VERSION ""

NS_ :

BS_:

BU_: ECP_Commanding_Node Modine_ECP
VAL_TABLE_ Bank_in_failsafe 1 "FAILSAFE" 0 "Not failsafe" ;
VAL_TABLE_ fan_inoperable_status 1 "Operational" 0 "INOPERABLE" ;
VAL_TABLE_ bank_status 3 "BANK_STATE_UNAVAILABLE" 2 "ALL_FANS_FAILED_IN_BANK" 1 "AT_LEAST_ONE_FAN_FAILD_IN_BANK" 0 "All Fans Operational" ;
VAL_TABLE_ FMI 0 "0 - Above normal (most severe)" 1 "1 - Below normal (most severe)" 2 "2 - Data erratic" 3 "3 - Voltage above normal" 4 "4 - Voltage below normal" 5 "5 - Current below normal" 6 "6 - Current above normal" 7 "7 - Mech system not responding" 8 "8 - Abnormal frequency" 9 "9 - Abnormal update rate" 10 "10 - Abnormal rate of change" 11 "11 - Root cause not known" 12 "12 - Bad intelligent device" 13 "13 - Out of calibration" 14 "14 - Special intstructions" 15 "15 - Above normal (least severe)" 16 "16 - Above normal (moderately)" 17 "17 - Below normal (least severe)" 18 "18 - Below normal (moderately)" 19 "19 - Recd network data in error" 20 "20 - Data drifted high" 21 "21 - Data drifted low" 31 "31 - Condition exists" ;
VAL_TABLE_ Ports 21 "Global (All ports)" 0 "Local" ;

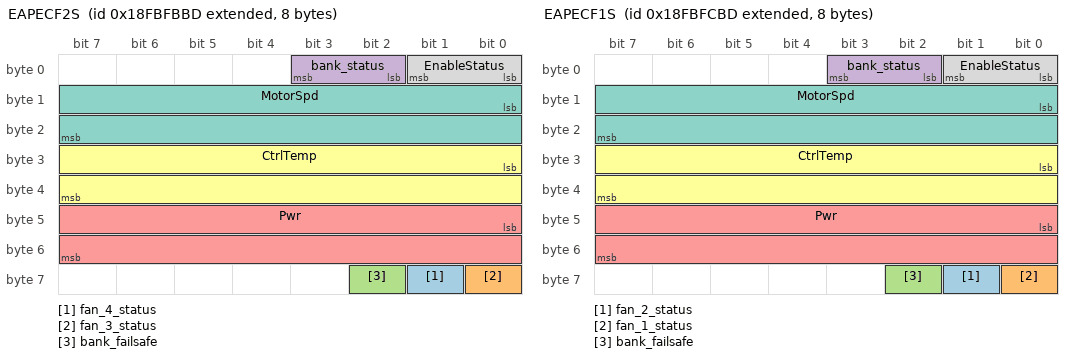
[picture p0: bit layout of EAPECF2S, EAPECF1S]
BO_ 2566650813 EAPECF2S: 8 Vector__XXX
 SG_ fan_4_status : 57|1@1+ (1,0) [0|1] "" Vector__XXX
 SG_ fan_3_status : 56|1@1+ (1,0) [0|1] "" Vector__XXX
 SG_ bank_failsafe : 58|1@1+ (1,0) [0|1] "" Vector__XXX
 SG_ bank_status : 2|2@1+ (1,0) [0|3] "" Vector__XXX
 SG_ Pwr : 40|16@1+ (0.5,0) [0|32127.5] "W" Vector__XXX
 SG_ CtrlTemp : 24|16@1+ (0.03125,-273) [-273|1734.96875] "°C" Vector__XXX
 SG_ MotorSpd : 8|16@1+ (0.5,0) [0|32127.5] "rpm" Vector__XXX
 SG_ EnableStatus : 0|2@1+ (1,0) [0|3] "" Vector__XXX

BO_ 2557984188 EAPECF2C: 8 Vector__XXX
 SG_ PercentSpdCmd : 24|8@1+ (0.5,0) [0|100] "%" Vector__XXX
 SG_ EnableCmd : 0|2@1+ (1,0) [0|3] "" Vector__XXX

BO_ 2566651069 EAPECF1S: 8 Modine_ECP
 SG_ fan_2_status : 57|1@1+ (1,0) [0|1] "" Vector__XXX
 SG_ fan_1_status : 56|1@1+ (1,0) [0|1] "" Vector__XXX
 SG_ bank_failsafe : 58|1@1+ (1,0) [0|1] "" Vector__XXX
 SG_ bank_status : 2|2@1+ (1,0) [0|3] "" Vector__XXX
 SG_ Pwr : 40|16@1+ (0.5,0) [0|32127.5] "W"  ECP_Commanding_Node
 SG_ CtrlTemp : 24|16@1+ (0.03125,-273) [-273|1734.96875] "°C"  ECP_Commanding_Node
 SG_ MotorSpd : 8|16@1+ (0.5,0) [0|32127.5] "rpm"  ECP_Commanding_Node
 SG_ EnableStatus : 0|2@1+ (1,0) [0|3] ""  ECP_Commanding_Node

BO_ 2558049724 EAPECF1C: 8 ECP_Commanding_Node
 SG_ PercentSpdCmd : 24|8@1+ (0.5,0) [0|100] "%"  Modine_ECP
 SG_ EnableCmd : 0|2@1+ (1,0) [0|3] ""  Modine_ECP

CM_ "1.0.0 - Iinitial Release";
CM_ BU_ ECP_Commanding_Node "Electronic control module in charge of controlling and coordinating the operation of a hybrid propulsion system.";
CM_ BO_ 2566650813 "Electrified Accessory Power Electronics Coolant Fan 1 Status
The status of electrified Accessory: Power Electronics Coolant Fan 1.   See PGN 30720 for the corresponding command message.";
CM_ SG_ 2566650813 Pwr "Calculated electrical power consumed by the Power Electronics Coolant Fan 1.";
CM_ SG_ 2566650813 CtrlTemp "A temperature measured and reported by the device.  It may be used for direct or remote (by another controller) control of the Fan 1.  For example, this may be the temperature of the fluid flowing through the Fan 1, or some other temperature ...";
CM_ SG_ 2566650813 MotorSpd "Motor Speed of the Power Electronics Coolant Fan 1.";
CM_ SG_ 2566650813 EnableStatus "Enable and direction status of the Power Electronics Coolant Fan 1 system or component.

00b = Accessory Motor Off
01b = Accessory Motor On - Normal, Forward, or Default Direction
10b = Accessory Motor On - Reverse Direction
11b = Not available";
CM_ BO_ 2557984188 "Electrified Accessory Power Electronics Coolant Fan 1 Command
The command message to the electrified accessory: Power Electronics Coolant Fan 1.  See PGN 64508 for the corresponding status message.";
CM_ SG_ 2557984188 PercentSpdCmd "Speed command to the Power Electronics Coolant Fan 1 in percentage of maximum speed.
Note: Both Speed Command and Percent Speed Command cannot be used at the same time.  Always set the unused speed command to Not Available.  If both commands are ...";
CM_ SG_ 2557984188 EnableCmd "Enable and direction command to the Power Electonics Coolant Fan 1.

00b = Accessory Motor Off
01b = Accessory Motor On Normal/Default Direction
10b = Accessory Motor On Reverse Direction
11b = Don't Care/Take no action";
CM_ BO_ 2566651069 "Electrified Accessory Power Electronics Coolant Fan 1 Status
The status of electrified Accessory: Power Electronics Coolant Fan 1.   See PGN 30720 for the corresponding command message.";
CM_ SG_ 2566651069 Pwr "Calculated electrical power consumed by the Power Electronics Coolant Fan 1.";
CM_ SG_ 2566651069 CtrlTemp "A temperature measured and reported by the device.  It may be used for direct or remote (by another controller) control of the Fan 1.  For example, this may be the temperature of the fluid flowing through the Fan 1, or some other temperature ...";
CM_ SG_ 2566651069 MotorSpd "Motor Speed of the Power Electronics Coolant Fan 1.";
CM_ SG_ 2566651069 EnableStatus "Enable and direction status of the Power Electronics Coolant Fan 1 system or component.

00b = Accessory Motor Off
01b = Accessory Motor On - Normal, Forward, or Default Direction
10b = Accessory Motor On - Reverse Direction
11b = Not available";
CM_ BO_ 2558049724 "Electrified Accessory Power Electronics Coolant Fan 1 Command
The command message to the electrified accessory: Power Electronics Coolant Fan 1.  See PGN 64508 for the corresponding status message.";
CM_ SG_ 2558049724 PercentSpdCmd "Speed command to the Power Electronics Coolant Fan 1 in percentage of maximum speed.
Note: Both Speed Command and Percent Speed Command cannot be used at the same time.  Always set the unused speed command to Not Available.  If both commands are ...";
CM_ SG_ 2558049724 EnableCmd "Enable and direction command to the Power Electonics Coolant Fan 1.

00b = Accessory Motor Off
01b = Accessory Motor On Normal/Default Direction
10b = Accessory Motor On Reverse Direction
11b = Don't Care/Take no action";
BA_DEF_ SG_  "J1939SLOT" STRING ;
BA_DEF_  "DBName" STRING ;
BA_DEF_  "DatabaseVersionDate" STRING ;
BA_DEF_  "BaudRate" STRING ;
BA_DEF_ SG_  "SigType" ENUM  "Default","Range","RangeSigned","ASCII","Discrete","Control","ReferencePGN","DTC","StringDelimiter","StringLength","StringLengthControl","MessageCounter","MessageChecksum";
BA_DEF_ SG_  "GenSigSendType" ENUM  "Cyclic","OnWrite","OnWriteWithRepetition","OnChange","OnChangeWithRepetition","IfActive","IfActiveWithRepetition","NoSigSendType";
BA_DEF_ SG_  "GenSigILSupport" ENUM  "No","Yes";
BA_DEF_ SG_  "GenSigEVName" STRING ;
BA_DEF_ SG_  "SPN" INT 0 524287;
BA_DEF_ BO_  "GenMsgILSupport" ENUM  "No","Yes";
BA_DEF_ BO_  "GenMsgRequestable" INT 0 1;
BA_DEF_ BO_  "GenMsgSendType" ENUM  "cyclic","NotUsed","NotUsed","NotUsed","NotUsed","NotUsed","NotUsed","IfActive","noMsgSendType";
BA_DEF_ BO_  "VFrameFormat" ENUM  "StandardCAN","ExtendedCAN","reserved","J1939PG";
BA_DEF_ BO_  "GenMsgCycleTime" INT 0 3600000;
BA_DEF_ BU_  "NmStationAddress" INT 0 255;
BA_DEF_ BU_  "NmJ1939Function" INT 0 255;
BA_DEF_  "SAE_J1939_DA_SpecVersion" STRING ;
BA_DEF_  "SAE_J1939_81_SpecVersion" STRING ;
BA_DEF_  "DatabaseVersion" STRING ;
BA_DEF_  "BusType" STRING ;
BA_DEF_  "ProtocolType" STRING ;
BA_DEF_  "SAE_J1939_75_SpecVersion" STRING ;
BA_DEF_  "SAE_J1939_21_SpecVersion" STRING ;
BA_DEF_  "SAE_J1939_73_SpecVersion" STRING ;
BA_DEF_  "SAE_J1939_71_SpecVersion" STRING ;
BA_DEF_DEF_  "J1939SLOT" "-";
BA_DEF_DEF_  "DBName" "";
BA_DEF_DEF_  "DatabaseVersionDate" "";
BA_DEF_DEF_  "BaudRate" "500K";
BA_DEF_DEF_  "SigType" "Default";
BA_DEF_DEF_  "GenSigSendType" "NoSigSendType";
BA_DEF_DEF_  "GenSigILSupport" "Yes";
BA_DEF_DEF_  "GenSigEVName" "Env@Nodename_@Signame";
BA_DEF_DEF_  "SPN" 0;
BA_DEF_DEF_  "GenMsgILSupport" "Yes";
BA_DEF_DEF_  "GenMsgRequestable" 1;
BA_DEF_DEF_  "GenMsgSendType" "noMsgSendType";
BA_DEF_DEF_  "VFrameFormat" "J1939PG";
BA_DEF_DEF_  "GenMsgCycleTime" 0;
BA_DEF_DEF_  "NmStationAddress" 254;
BA_DEF_DEF_  "NmJ1939Function" 0;
BA_DEF_DEF_  "SAE_J1939_DA_SpecVersion" "";
BA_DEF_DEF_  "SAE_J1939_81_SpecVersion" "";
BA_DEF_DEF_  "DatabaseVersion" "";
BA_DEF_DEF_  "BusType" "";
BA_DEF_DEF_  "ProtocolType" "";
BA_DEF_DEF_  "SAE_J1939_75_SpecVersion" "";
BA_DEF_DEF_  "SAE_J1939_21_SpecVersion" "";
BA_DEF_DEF_  "SAE_J1939_73_SpecVersion" "";
BA_DEF_DEF_  "SAE_J1939_71_SpecVersion" "";
BA_ "SAE_J1939_DA_SpecVersion" "2020-01";
BA_ "SAE_J1939_81_SpecVersion" "2017-03";
BA_ "DatabaseVersion" "1.0.0";
BA_ "BusType" "CAN";
BA_ "ProtocolType" "J1939";
BA_ "SAE_J1939_75_SpecVersion" "2015-11";
BA_ "SAE_J1939_21_SpecVersion" "2018-10";
BA_ "SAE_J1939_73_SpecVersion" "2019-01";
BA_ "SAE_J1939_71_SpecVersion" "2020-02";
BA_ "DatabaseVersionDate" "5-Oct-2023";
BA_ "DBName" "Modine_ECP";
BA_ "NmStationAddress" BU_ ECP_Commanding_Node 90;
BA_ "NmStationAddress" BU_ Modine_ECP 78;
BA_ "NmJ1939Function" BU_ Modine_ECP 58;
BA_ "GenMsgCycleTime" BO_ 2566650813 1000;
BA_ "GenMsgSendType" BO_ 2566650813 0;
BA_ "GenMsgCycleTime" BO_ 2557984188 1000;
BA_ "GenMsgSendType" BO_ 2557984188 0;
BA_ "GenMsgSendType" BO_ 2566651069 0;
BA_ "GenMsgCycleTime" BO_ 2566651069 1000;
BA_ "GenMsgSendType" BO_ 2558049724 0;
BA_ "GenMsgCycleTime" BO_ 2558049724 1000;
BA_ "SigType" SG_ 2566650813 Pwr 1;
BA_ "SPN" SG_ 2566650813 Pwr 8012;
BA_ "SigType" SG_ 2566650813 CtrlTemp 1;
BA_ "SPN" SG_ 2566650813 CtrlTemp 8011;
BA_ "SigType" SG_ 2566650813 MotorSpd 1;
BA_ "SPN" SG_ 2566650813 MotorSpd 8010;
BA_ "SigType" SG_ 2566650813 EnableStatus 5;
BA_ "SPN" SG_ 2566650813 EnableStatus 8007;
BA_ "SigType" SG_ 2557984188 PercentSpdCmd 1;
BA_ "SPN" SG_ 2557984188 PercentSpdCmd 8006;
BA_ "SigType" SG_ 2557984188 EnableCmd 4;
BA_ "SPN" SG_ 2557984188 EnableCmd 8003;
BA_ "SigType" SG_ 2566651069 Pwr 1;
BA_ "SPN" SG_ 2566651069 Pwr 8012;
BA_ "SigType" SG_ 2566651069 CtrlTemp 1;
BA_ "SPN" SG_ 2566651069 CtrlTemp 8011;
BA_ "SigType" SG_ 2566651069 MotorSpd 1;
BA_ "SPN" SG_ 2566651069 MotorSpd 8010;
BA_ "SigType" SG_ 2566651069 EnableStatus 5;
BA_ "SPN" SG_ 2566651069 EnableStatus 8007;
BA_ "SigType" SG_ 2558049724 PercentSpdCmd 1;
BA_ "SPN" SG_ 2558049724 PercentSpdCmd 8006;
BA_ "SigType" SG_ 2558049724 EnableCmd 4;
BA_ "SPN" SG_ 2558049724 EnableCmd 8003;
VAL_ 2566650813 fan_4_status 1 "Operational" 0 "INOPERABLE" ;
VAL_ 2566650813 fan_3_status 1 "Operational" 0 "INOPERABLE" ;
VAL_ 2566650813 bank_failsafe 1 "FAILSAFE" 0 "Not failsafe" ;
VAL_ 2566650813 bank_status 3 "BANK_STATE_UNAVAILABLE" 2 "ALL_FANS_FAILED_IN_BANK" 1 "AT_LEAST_ONE_FAN_FAILD_IN_BANK" 0 "All Fans Operational" ;
VAL_ 2566650813 EnableStatus 3 "Not available" 2 "Accessory Motor On, Reverse Direction" 1 "Accessory Motor On, Normal" 0 "Accessory Motor Off" ;
VAL_ 2557984188 EnableCmd 3 "Don't Care/Take no action" 2 "Accessory Motor On Reverse Direction" 1 "Accessory Motor On Normal/Default Direction" 0 "Accessory Motor Off" ;
VAL_ 2566651069 fan_2_status 1 "Operational" 0 "INOPERABLE" ;
VAL_ 2566651069 fan_1_status 1 "Operational" 0 "INOPERABLE" ;
VAL_ 2566651069 bank_failsafe 1 "FAILSAFE" 0 "Not failsafe" ;
VAL_ 2566651069 bank_status 3 "BANK_STATE_UNAVAILABLE" 2 "ALL_FANS_FAILED_IN_BANK" 1 "AT_LEAST_ONE_FAN_FAILD_IN_BANK" 0 "All Fans Operational" ;
VAL_ 2566651069 EnableStatus 3 "Not available" 2 "Accessory Motor On, Reverse Direction" 1 "Accessory Motor On, Normal" 0 "Accessory Motor Off" ;
VAL_ 2558049724 EnableCmd 3 "Don't Care/Take no action" 2 "Accessory Motor On Reverse Direction" 1 "Accessory Motor On Normal/Default Direction" 0 "Accessory Motor Off" ;
